# RZT2H register map
Vendor: Renesas Electronics Corporation; Series: RZT; File version: 1.00.00
CPU: other r0p0, little endian, MPU, no FPU, VTOR, 4 interrupt priority bits, 624 interrupts
Registers are 32-bit, read-write, reset 0x0 unless marked. A register's access mark holds for its fields unless they carry their own. Offsets are from the block's base; [hi:lo] are bit positions.

## USBHC — USB 2.0 HS Host Module
Base 0x92040000
0x00 HCREVISION ro reset 0x10
  [7:0] REV — HCI revision
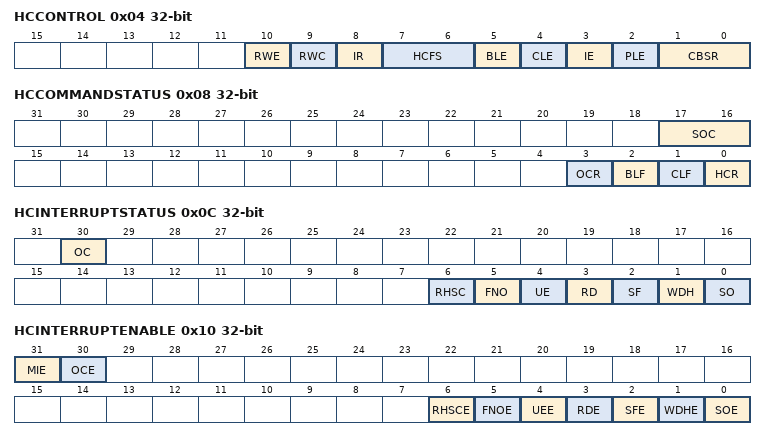
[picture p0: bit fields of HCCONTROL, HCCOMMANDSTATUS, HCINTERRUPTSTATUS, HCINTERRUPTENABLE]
0x04 HCCONTROL
  [10] RWE — PME assertion control (RemoteWakeUpEnable)
  [9] RWC — Remote Wakeup support setting (RemoteWakeUpConnect)
    0=Remote Wakeup is not supported; 1=Remote Wakeup is supported
  [8] IR — HcInterruptStatus interrupt path setting (InterruptRouting)
  [7:6] HCFS — Host logic operation status (Host Controller FunctionalState)
    0=USB Reset; 1=USB Resume; 2=USB Operational; 3=USB Suspend
  [5] BLE — Bulk list processing setting (BulkListEnable)
    0=Bulk list processing is not done; 1=Bulk list processing is done
  [4] CLE — Control list processing setting (ControlListEnable)
    0=Control list processing is not done; 1=Control list processing is done
  [3] IE — Isochronous ED processing setting (IsochronousEnable)
    0=Isochronous ED processing is enabled; 1=Isochronous ED processing is disabled
  [2] PLE — Periodic list setting (PeriodicListEnable)
    0=Periodic list processing is not done; 1=Period list processing is done
  [1:0] CBSR — Control/bulk transfer service ratio (ControlBulkServiceRatio)
0x08 HCCOMMANDSTATUS
  [17:16] SOC ro — Schedule overrun count (Scheduling OverrunCount)
  [3] OCR wo — Host logic control right change (OwnershipChangeRequest)
  [2] BLF — Bulk list TD (BulkListFilled)
    0=TD exists in the bulk list; 1=TD does not exist in the bulk list
  [1] CLF — Control list TD (ControlList Filled)
    0=TD exists in the control list; 1=TD does not exist in the control list
  [0] HCR wo — Host logic software reset start (HostController Reset)
0x0C HCINTERRUPTSTATUS
  [30] OC — Host logic control right change (OwnershipChange)
  [6] RHSC — HcRhStatus/HcRhPortStatus register status (RootHubStatus Change)
    0=No RHSC interrupt has occurred; 1=RHSC interrupt has occurred
  [5] FNO — FrameNumber bit MSB change (Frame Number Overflow)
    0=No FNO interrupt has occurred; 1=FNO interrupt has occurred
  [4] UE — USB non-related system error detection (Unrecoverable Error)
    0=No UE interrupt has occurred; 1=UE interrupt has occurred
  [3] RD — Resume detection (Resume Detected)
    0=No RD interrupt has occurred; 1=RD interrupt has occurred
  [2] SF — HccaFrameNumber update (StartOfFrame)
    0=No SF interrupt has occurred; 1=SF interrupt has occurred
  [1] WDH — Host logic HccaDoneHead update (Writeback Done Head)
    0=No WDH interrupt has occurred; 1=WDH interrupt has occurred
  [0] SO — USB schedule overrun (Scheduling Overrun)
    0=No SO interrupt has occurred; 1=SO interrupt has occurred
0x10 HCINTERRUPTENABLE
  [31] MIE — Interrupt 8 source enable (MasterInterrupt Enable)
    0=No monitoring and nothing is to be done; 1=The specified interrupt is enabled
  [30] OCE — OC interrupt source enable (OwnershipChangeEnable)
    0=No monitoring and nothing is to be done; 1=OC interrupt is enabled
  [6] RHSCE — RHSC interrupt source enable (RootHubStatus ChangeEnable)
    0=No monitoring and nothing is to be done; 1=RHSC interrupt is enabled
  [5] FNOE — FNO interrupt source enable (FrameNumber OverflowEnable)
    0=No monitoring and nothing is to be done; 1=FNO interrupt is enabled
  [4] UEE — UE interrupt source enable (Unrecoverable ErrorEnable)
    0=No monitoring and nothing is to be done; 1=UE interrupt is enabled
  [3] RDE — RD interrupt source enable (Resume DetectedEnable)
    0=No monitoring and nothing is to be done; 1=RD interrupt is enabled
  [2] SFE — SF interrupt source enable (StartOfFrame)
    0=No monitoring and nothing is to be done; 1=SF interrupt is enabled
  [1] WDHE — WDH interrupt source enable (WritebackDone HeadEnable)
    0=No monitoring and nothing is to be done; 1=WDH interrupt is enabled
  [0] SOE — SO interrupt source enable (Scheduling OverrunEnable)
    0=No monitoring and nothing is to be done; 1=SO interrupt is enabled
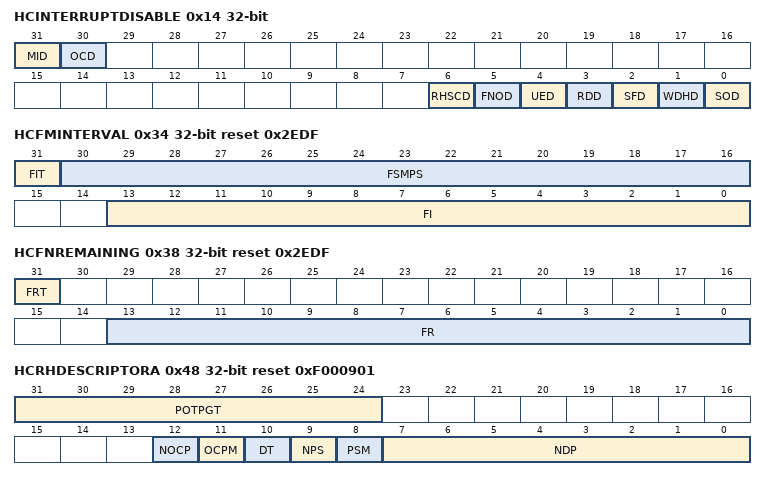
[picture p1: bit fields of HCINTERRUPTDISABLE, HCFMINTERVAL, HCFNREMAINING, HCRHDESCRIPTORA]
0x14 HCINTERRUPTDISABLE
  [31] MID — Interrupt 8 source disable (Master Interrupt Disable)
    0=Nothing is to be done; 1=The interrupt set is disabled
  [30] OCD — OC interrupt source disable (OwnershipChangeDisable)
    0=Nothing is to be done; 1=OC is deleted from the interrupt sources
  [6] RHSCD — RHSC interrupt source disable (RootHub StatusChange Disable)
    0=Nothing is to be done; 1=The interrupt source RHSC is disabled
  [5] FNOD — FNO interrupt source disable (FrameNumberOverflow Disable)
    0=Nothing is to be done; 1=The interrupt source FNO is disabled
  [4] UED — UE interrupt source disable (Unrecoverable ErrorDisable)
    0=Nothing is to be done; 1=The interrupt source UE is disabled
  [3] RDD — RD interrupt source disable (Resume Detected Disable)
    0=Nothing is to be done; 1=The interrupt source RD is disabled
  [2] SFD — SF interrupt source disable (StartOfFrame Disable)
    0=Nothing is to be done; 1=The interrupt source SF is disabled
  [1] WDHD — WDH interrupt source disable (Writeback DoneHead Disable)
    0=Nothing is to be done; 1=The interrupt source WDH is disabled
  [0] SOD — SO interrupt source disable (Scheduling Overrun Disable)
    0=Nothing is to be done; 1=The interrupt source SO is disabled
0x18 HCHCCA
  [31:8] RAMBA — RAM base address setting
0x1C HCPERIODCCURRENTIED ro — HcPeriodicCurrentED Register
  [31:4] PCED — ED physical address (PeriodicCurrentED)
0x20 HCCONTROLHEADED
  [31:4] CHED — Start ED physical address (ControlHeadED)
0x24 HCCONTROLCURRENTED
  [31:4] CCED — ED physical address (ControlCurrentED)
0x28 HCBULKHEADED
  [31:4] BHED — Start ED physical address (BulkHeadED)
0x2C HCBULKCURRENTED
  [31:4] BCED — ED physical address (BulkCurrentED)
0x30 HCDONEHEAD ro
  [31:4] DH — HcDoneHead physical address (DoneHead)
0x34 HCFMINTERVAL reset 0x2EDF
  [31] FIT — Frame synchronization (FrameInterval Toggle)
  [30:16] FSMPS — FS transfer packet maximum size setting (FSLagest DataPacket)
  [13:0] FI — Frame interval setting (FrameInterval)
0x38 HCFNREMAINING ro reset 0x2EDF — HcFmRemaining Register
  [31] FRT — Frame synchronization (FrameRemainingToggle)
  [13:0] FR — Down counter frame (FrameRemaining)
0x3C HCFMNUMBER ro
  [15:0] FN — Elapsed frame number (FrameNumber)
0x40 HCPERIODSTART — HcPeriodicStart Register
  [13:0] PS — Periodic list processing start time (PeriodicStart)
0x44 HCLSTHRESHOLD reset 0x628
  [11:0] LS — Transferrable threshold (LSThreshold)
0x48 HCRHDESCRIPTORA reset 0xF000901
  [31:24] POTPGT — Wait time (PowerOnToPowerGood Time)
  [12] NOCP — Overcurrent function support (NoOver Current Protection)
    0=Overcurrent protection function is supported; 1=Overcurrent protection function is not supported
  [11] OCPM — Overcurrent state reporting (OverCurrentProtection Mode)
    0=Overcurrent state of all ports is collectively reported; 1=Overcurrent state of each port is separately reported
  [10] DT ro — Device type (DeviceType)
  [9] NPS — Power control (NoPower Switching)
    0=Port power can be switched on and off; 1=Port power is always turned on while the host logic is operating
  [8] PSM — Power switch control (PowerSwitchingMode)
    0=Power to all ports is controlled together; 1=Power to each port is separately controlled
  [7:0] NDP ro — Downstream port number (NumberDownstreamPorts)
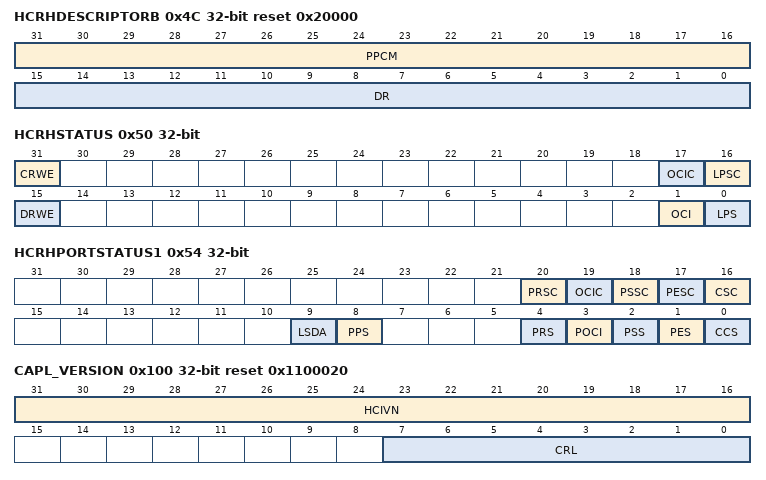
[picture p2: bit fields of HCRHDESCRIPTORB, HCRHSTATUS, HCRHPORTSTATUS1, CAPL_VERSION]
0x4C HCRHDESCRIPTORB reset 0x20000
  [31:16] PPCM — Port Power Control Mask
  [15:0] DR — Device Removable
0x50 HCRHSTATUS
  [31] CRWE wo — DRWE bit clear (Clear Remote Wakeup Enable)
    0=No effect; 1=Clears the DRWE bit
  [17] OCIC — OCI bit change report (OverCurrent Indicate Change)
    0=Nothing is to be done in case of an overcurrent; 1=OverCurrent state has changed
  [16] LPSC — Local power status change (LocalPowerStatusChange)
  [15] DRWE — Device remote start enable (DeviceRemoteWakeupEnable)
    0=ConnectStatusChange is not a RemoteWakeup source; 1=ConnectStatusChange is a RemoteWakeup source
  [1] OCI ro — Overcurrent indicator (OverCurrent Indicator)
    0=Port is in normal state; 1=Port is in overcurrent state
  [0] LPS — Local power status (LocalPowerStatus)
0x54 HCRHPORTSTATUS1
  [20] PRSC — Port reset complete (PortReset StatusChange)
    0=Port reset has not been completed, or nothing is to be done regarding the PRS bit; 1=Port reset has been completed
  [19] OCIC — Overcurrent state detection (OverCurrent IndicateChange)
    0=Nothing is to be done regarding overcurrent state; 1=Overcurrent state has changed
  [18] PSSC — RESUME sequence complete (PortSuspend StatusChange)
    0=RESUME has not been completed; 1=RESUME has been completed
  [17] PESC — PES bit status (PortEnable StatusChange)
    0=Nothing is to be done regarding PES; 1=PES state has changed
  [16] CSC — CCS bit status (ConnectStatus Change)
    0=Nothing is to be done regarding CCS; 1=CCS has changed
  [9] LSDA — Device speed (LowSpeedDeviceAttached)
    0=FS device is connected; 1=LS device is connected
  [8] PPS — Power status (PortPowerStatus)
    0=Port power is off; 1=Port power is on
  [4] PRS — Port reset status (PortResetStatus)
    0=Port reset is not in progress; 1=Port reset is in progress
  [3] POCI ro — Downstream port overcurrent detection (PortOverCurrentIndicator)
    0=Port is in normal state; 1=Port is in overcurrent state
  [2] PSS — Suspend/Resume status (PortSuspendStatus)
    0=Port is in normal transfer state; 1=Port is in suspend state
  [1] PES — Port enable status (PortEnableStatus)
    0=Port is disabled; 1=Port is enabled
  [0] CCS — Connection status indication (CurrentConnectStatus)
    0=No device is connected; 1=Device is connected
0x100 CAPL_VERSION ro reset 0x1100020 — Capability Registers Length and EHCI Version Number Register
  [31:16] HCIVN — EHCI Version Number
  [7:0] CRL — Capability Registers Length
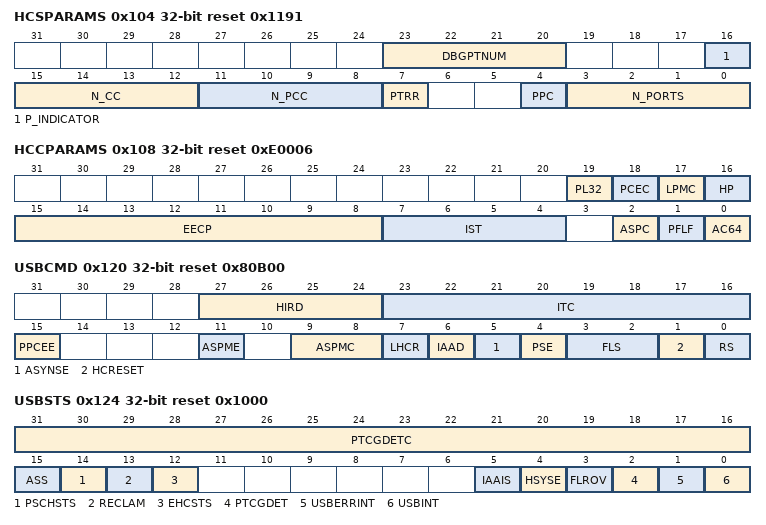
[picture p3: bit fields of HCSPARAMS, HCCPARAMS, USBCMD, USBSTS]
0x104 HCSPARAMS ro reset 0x1191 — Structural Parameters Register
  [23:20] DBGPTNUM — Debug port number
  [16] P_INDICATOR — Port indicator control support
  [15:12] N_CC — Number of OHCI host logic (Number of Companion Controller)
  [11:8] N_PCC — Number of ports (Number of Ports per Companion Controller)
  [7] PTRR — Port routing rules
  [4] PPC — Port power control (Port Power Control)
    0=Port power is always on; 1=Port power is controlled using bit 12 (PP) in the PORTSC1 register
  [3:0] N_PORTS — Number of downstream ports (Number of Ports)
    1=1 port; other=Others (Reserved)
0x108 HCCPARAMS ro reset 0xE0006 — Capability Parameters Register
  [19] PL32 — 32-frame periodic list capability
  [18] PCEC — Per-port change event capability
  [17] LPMC — Link power management capability
  [16] HP — Hardware prefetch capability
  [15:8] EECP — Offset address (EHCI Extend Capabilities Pointer)
  [7:4] IST — Isochronous data structure threshold
  [2] ASPC — Asynchronous schedule park support capability
  [1] PFLF — Programming frame list flag
  [0] AC64 — Memory pointer selection
0x10C HCSP_PORTROUTE ro — Companion Port Route Description Register
0x120 USBCMD reset 0x80B00 — USB Command Register
  [27:24] HIRD — Host-Initiated Resume Duration (Minimum K-state drive time)
  [23:16] ITC — Host logic interrupt generation maximum rate (Interrupt Threshold Control)
    1=1 micro-frame; 2=2 micro-frames; 4=4 micro-frames; 8=8 micro-frames (1 ms); 16=16 micro-frames (2 ms); 32=32 micro-frames (4 ms); 64=64 micro-frames (8 ms)
  [15] PPCEE — Per-port change event enable
  [11] ASPME — Asynchronous schedule park mode enable
    0=Disabled; 1=Enabled
  [9:8] ASPMC — Asynchronous schedule park mode count
  [7] LHCR ro — Light host controller reset execution status
  [6] IAAD — Interrupt on Async Advance Doorbell
  [5] ASYNSE — Asynchronous schedule enable
    0=Asynchronous list processing is not executed (skipped); 1=Asynchronous list processing is executed using the ASYNCLISTADDR register
  [4] PSE — Periodic schedule enable
    0=Periodic list processing is not executed (skipped); 1=Periodic list processing is executed using the PERIODICLISTBASE register
  [3:2] FLS — Frame list size
    0=1024 elements (4096 bytes); 1=512 elements (2048 bytes); 2=256 elements (1024 bytes); 3=32 elements (128 bytes)
  [1] HCRESET — Host logic initialization (Host Controller Reset)
  [0] RS — EHCI host logic run/stop (Run/Stop)
    0=Stopped (the host logic has completed transactions and halted); 1=Activated (the host logic executes the schedule)
0x124 USBSTS reset 0x1000 — USB Status Register
  [31:16] PTCGDETC — Port-n Change Detect
  [15] ASS ro — Asynchronous schedule status
    0=Asynchronous schedule is disabled; 1=Asynchronous schedule is enabled
  [14] PSCHSTS ro — Periodic schedule status
    0=Periodic schedule is disabled; 1=Periodic schedule is enabled
  [13] RECLAM ro — Empty asynchronous schedule detection (Reclamation)
  [12] EHCSTS ro — EHCI host logic status (HCHalted)
    0=EHCI host logic is in execution; 1=EHCI host logic is stopped
  [5] IAAIS — Async advance interrupt status
    0=No Async Advance interrupt has occurred; 1=Async Advance interrupt state has been detected
  [4] HSYSE — Host system error
    0=No system error has occurred; 1=System error has occurred
  [3] FLROV — Frame list rollover
    0=Frame list has not returned to 0x000; 1=Frame list has returned to 0x000
  [2] PTCGDET — Port state change detection
  [1] USBERRINT — USB transaction status (USB Error Interrupt)
    0=USB transaction has been completed normally; 1=USB transaction has ended with an error
  [0] USBINT — USB transfer complete (USB Interrupt)
    0=USB transfer has not been completed; 1=USB transfer has been completed
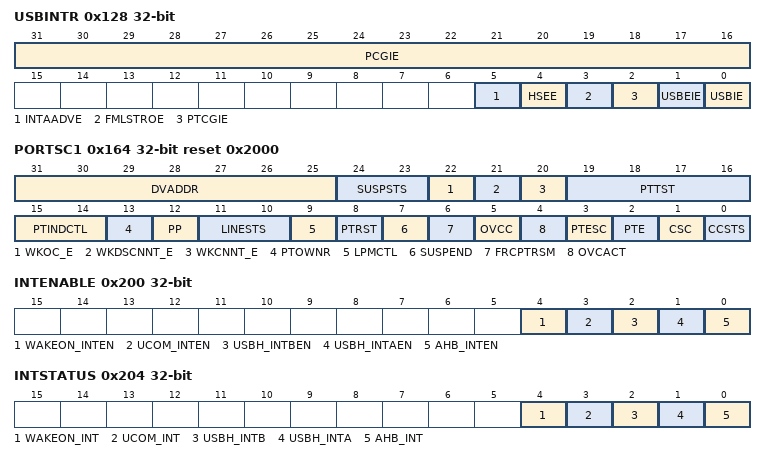
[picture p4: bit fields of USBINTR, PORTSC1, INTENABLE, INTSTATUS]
0x128 USBINTR — USB Interrupt Enable Register
  [31:16] PCGIE — Port-n Change Interrupt Enable
  [5] INTAADVE — Interrupt on async advance enable
    0=Disabled; 1=Enabled (interrupt indicated by the Interrupt on Async Advance bit)
  [4] HSEE — Host system error enable
    0=Disabled; 1=Enabled (interrupt indicated by the Host System Error bit)
  [3] FMLSTROE — Frame list rollover enable
    0=Disabled; 1=Enabled (interrupt indicated by the Frame List Rollover bit)
  [2] PTCGIE — Port change interrupt enable
    0=Disabled; 1=Enabled (interrupt indicated by the Port Change Detect bit)
  [1] USBEIE — USB error interrupt enable
    0=Disabled; 1=Enabled (interrupt indicated by the USBERRINT bit)
  [0] USBIE — USB interrupt enable
    0=Disabled; 1=Enabled (interrupt indicated by the USBINT bit)
0x12C FRINDEX — USB Frame Index Register
  [13:0] FRAMEINDEX
0x130 CTRLDSSEGMENT ro — Control Data Structure Segment Register
0x134 PERIODICLISTBASE — Periodic Frame List Base Address Register
  [31:12] PFLSA — Periodic frame list start address
0x138 ASYNCLISTADDR — Next Asynchronous List Address Register
  [31:5] LPL — Asynchronous Queue Head link pointer address (Link Pointer Low)
0x160 CONFIGFLAG — Configure Flag Register
  [0] CF — Port routing control circuit configuration flag (Configure Flag)
    0=Port routing control circuit routes each port to the OHCI host logic by default; 1=Port routing control circuit routes each port to the EHCI host logic by default
0x164 PORTSC1 reset 0x2000 — Port 1 Status and Control Register
  [31:25] DVADDR — USB device address
  [24:23] SUSPSTS — Suspend status
    0=Device successfully entered the L1 state (ACK is received from the device); 1=Device was unable to enter the L1 state at this time (NYET is received from the device); 2=Device does not support L1 state transitions (STALL is received from the device); 3=Other than above (such as a timeout error)
  [22] WKOC_E — Overcurrent state detection enable (Wake on Over-current Enable)
  [21] WKDSCNNT_E — Device disconnection detection enable (Wake on Disconnect Enable)
  [20] WKCNNT_E — Device connection detection enable (Wake on Connect Enable)
  [19:16] PTTST — Pin test control
  [15:14] PTINDCTL ro — As the host logic does not support the port indicator control function, these bits are set to 00b.
  [13] PTOWNR — Port ownership
    0=EHCI has the port ownership; 1=OHCI has the port ownership
  [12] PP — Port Power Supply Control (Port Power)
    0=No power is supplied to the port; 1=Power is supplied to the port
  [11:10] LINESTS ro — D+/D- logic level
  [9] LPMCTL — LPM control
    0=Suspend using L2; 1=Suspend using L1 (LPM)
  [8] PTRST — Port reset status
    0=Port is not in reset state; 1=Port is in reset state
  [7] SUSPEND — Port suspend
    0=Port is not in suspend state; 1=Port is in suspend state
  [6] FRCPTRSM — Force Port Resume (Port resume detection flag)
    0=Resume (K-state) has not been detected or output; 1=Resume (K-state) has been detected or output
  [5] OVCC — Over-current Change
    0=Value of bit 4 (OVCACT) has not changed; 1=Value of bit 4 (OVCACT) has changed
  [4] OVCACT ro — Port overcurrent status
    0=Port is not in overcurrent state; 1=Port is in overcurrent state
  [3] PTESC — Port enable/disable status change
    0=Frame babble error has not occurred; 1=Frame babble error has been detected
  [2] PTE — Port enable/disable status
    0=Port is disabled; 1=Port is enabled
  [1] CSC — Connect status change
    0=Value of bit 0 (Current Connect Status) has not changed; 1=Value of bit 0 (Current Connect Status) has changed
  [0] CCSTS ro — Port connection status
    0=No device is connected to the port; 1=Device is connected to the port
0x200 INTENABLE
  [all] fields
    0=Disabled; 1=Enabled
  [4] WAKEON_INTEN — WAKEON_INT bit control
  [3] UCOM_INTEN — UCOM_INT bit control
  [2] USBH_INTBEN — USBH_INTB bit control
  [1] USBH_INTAEN — USBH_INTA bit control
  [0] AHB_INTEN — AHB_INT bit control
0x204 INTSTATUS
  [4] WAKEON_INT — WAKEON interrupt status
    0=WAKEON interrupt has not occurred; 1=WAKEON interrupt has occurred
  [3] UCOM_INT ro — UCOM register interrupt status
    0=UCOM register interrupt has not occurred; 1=UCOM register interrupt has occurred
  [2] USBH_INTB ro — USBH_INTB EHCI interrupt status
    0=INTB interrupt has not occurred; 1=INTB interrupt has occurred
  [1] USBH_INTA ro — OHCI interrupt status
    0=INTA interrupt has not occurred; 1=INTA interrupt has occurred
  [0] AHB_INT — AHB bus error indication
    0=AHB bus error has not occurred; 1=AHB bus error has occurred
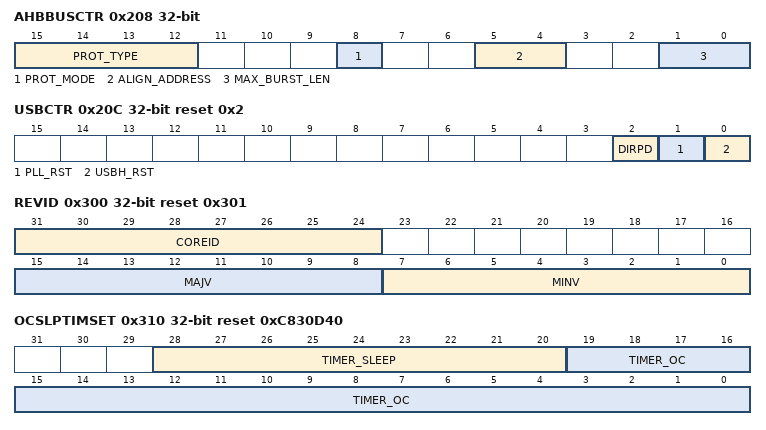
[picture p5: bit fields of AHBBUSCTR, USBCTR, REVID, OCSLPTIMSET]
0x208 AHBBUSCTR
  [15:12] PROT_TYPE — These bits set MHPROT[3:0] when the AHB master interface initiates a transfer.
  [8] PROT_MODE — This bit selects the MHPROT[3:0] mode when the AHB master interface initiates a transfer.
    0=Value of PROT_TYPE[3:0] is output as MHPROT[3:0]; 1=0000b is set as MHPROT[3:0] for DMA transfer when the last data of a burst is transferred. The value of PROT_TYPE[3:0] is used as MHPROT[3:0] for other data in a burst.
  [5:4] ALIGN_ADDRESS — Address boundary setting
    0=1-KB boundary is not exceeded when initiating a burst transfer; 1=64-byte boundary is not exceeded when initiating a burst transfer; 2=32-byte boundary is not exceeded when initiating a burst transfer (The maximum burst length is INCR8 in this case. The 32-byte boundary is exceeded when the maximum burst length is INCR16.); 3=16-byte boundary is not exceeded when initiating a burst transfer. (The maximum burst length is INCR4 in this case. The 16-byte boundary is exceeded when the maximum burst length is INCR8 or greater.)
  [1:0] MAX_BURST_LEN — Maximum burst length
    0=INCR16; 1=INCR8; 2=INCR4; 3=SINGLE
0x20C USBCTR reset 0x2
  [2] DIRPD — Direct transition to power-down state
    0=Normal operation; 1=Direct power-down state
  [1] PLL_RST — Reset of USB PHY PLL
    0=Release PLL reset; 1=Assert PLL reset
  [0] USBH_RST wo — Software reset for the core
    0=Nothing occurs; 1=Host logic is reset
0x300 REVID ro reset 0x301 — Revision and Core ID Register
  [31:24] COREID
  [15:8] MAJV — Major Version
  [7:0] MINV — Minor Version
0x310 OCSLPTIMSET reset 0xC830D40 — Overcurrent Detection/Sleep Timer Setting Register
  [28:20] TIMER_SLEEP — Detection/Sleep Timer Setting
  [19:0] TIMER_OC — Overcurrent Timer setting
0x800 COMMCTRL reset 0x80000000 — Common Control Register
  [31] PERI — USB mode setting
    0=Host mode; 1=Function mode
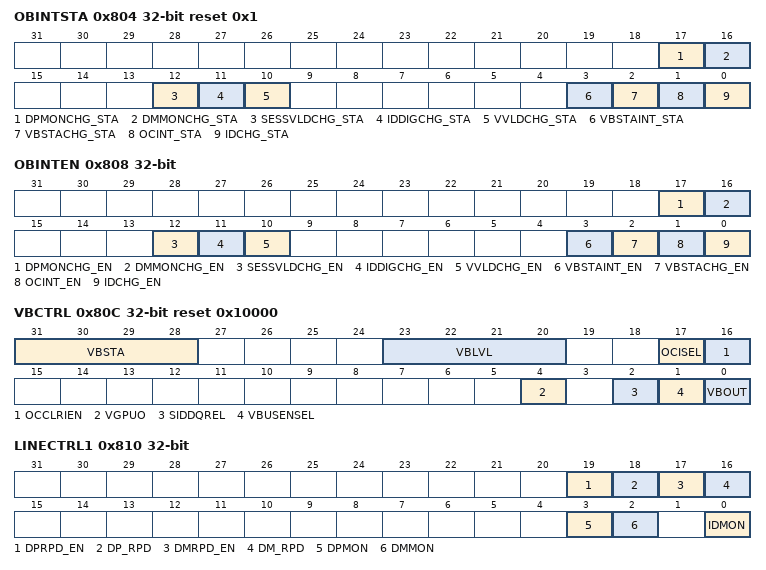
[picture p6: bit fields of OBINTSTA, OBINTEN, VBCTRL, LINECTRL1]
0x804 OBINTSTA reset 0x1 — OTG-BC Interrupt Status Register
  [17] DPMONCHG_STA — DPMON change status
    0=The DPMON bit of the LINECTRL1 register has not changed; 1=The DPMON bit of the LINECTRL1 register has changed
  [16] DMMONCHG_STA — DMMON change status
    0=The DMMON bit of the LINECTRL1 register has not changed; 1=The DMMON bit of the LINECTRL1 register has changed
  [12] SESSVLDCHG_STA — OTGSESSVLD change status
    0=The OTGSESSVLD bit of the PHYCTRL register has not changed; 1=The OTGSESSVLD bit of the PHYCTRL register has changed
  [11] IDDIGCHG_STA — IDDIG0 change status
    0=The IDDIG0 bit of the PHYCTRL register has not changed; 1=The IDDIG0 bit of the PHYCTRL register has changed
  [10] VVLDCHG_STA — VBUSVALID change status
    0=The VBUSVALID bit of the PHYCTRL register has not changed; 1=The VBUSVALID bit of the PHYCTRL register has changed
  [3] VBSTAINT_STA — VBUS voltage status interrupt
    0=Value of VBSTA[3:0] bits is not the same as the value of the VBLVL[3:0] bits; 1=Value of VBSTA[3:0] bits is the same as the value of the VBLVL[3:0] bits
  [2] VBSTACHG_STA — VBSTA[3:0] change status
    0=Value of the VBSTA[3:0] bits has not changed; 1=Value of the VBSTA[3:0] bits has changed
  [1] OCINT_STA — USB_OVRCUR assertion status
    0=USB_OVRCUR pin is not asserted (remains 1); 1=USB_OVRCUR pin is asserted (change to 0)
  [0] IDCHG_STA — USB_OTG_ID change status
    0=Value input from the USB_OTG_ID pin has not changed; 1=Value input from the USB_OTG_ID pin has changed
0x808 OBINTEN — OTG-BC Interrupt Enable Register
  [17] DPMONCHG_EN — DPMONCHG_STA interrupt enable
    0=Interrupt flagged by the DPMONCHG_STA bit disabled; 1=Interrupt flagged by the DPMONCHG_STA bit enabled
  [16] DMMONCHG_EN — DMMONCHG_STA interrupt enable
    0=Interrupt flagged by the DMMONCHG_STA bit disabled; 1=Interrupt flagged by the DMMONCHG_STA bit enabled
  [12] SESSVLDCHG_EN — SESSVLDCHG_STA interrupt enable
    0=Interrupt flagged by the SESSVLDCHG_STA bit disabled; 1=Interrupt flagged by the SESSVLDCHG_STA bit enabled
  [11] IDDIGCHG_EN — IDDIGCHG_STA interrupt enable
    0=Interrupt flagged by the IDDIGCHG_STA bit disabled; 1=Interrupt flagged by the IDDIGCHG_STA bit enabled
  [10] VVLDCHG_EN — VVLDCHG_STA interrupt enable
    0=Interrupt flagged by the VVLDCHG_STA bit disabled; 1=Interrupt flagged by the VVLDCHG_STA bit enabled
  [3] VBSTAINT_EN — VBSTAINT_STA interrupt enable
    0=Interrupt flagged by the VBSTAINT_STA bit is disabled; 1=Interrupt flagged by the VBSTAINT_STA bit is enabled
  [2] VBSTACHG_EN — VBSTACHG_STA interrupt enable
    0=Interrupt flagged by the VBSTACHG_STA bit is disabled; 1=Interrupt flagged by the VBSTACHG_STA bit is enabled
  [1] OCINT_EN — OCINT_STA interrupt enable
    0=Interrupt flagged by the OCINT_STA bit is disabled; 1=Interrupt flagged by the OCINT_STA bit is enabled
  [0] IDCHG_EN — IDCHG_STA Interrupt enable
    0=Interrupt flagged by the IDCHG_STA bit is disabled; 1=Interrupt flagged by the IDCHG_STA bit is enabled
0x80C VBCTRL reset 0x10000 — VBUS Control Register
  [31:28] VBSTA ro — VBUS indication
  [23:20] VBLVL — VBUS level detection
  [17] OCISEL — Overcurrent detection
    0=OCI signal that is output by the host logic This signal is treated as an indication of an overcurrent if the USB_OVRCUR pin is asserted longer than the overcurrent detection time set in bits [19:0] (TIMER_OC[19:0]) in the OCSLPTIMSET register; 1=Inverted signal from the USB_OVRCUR pin When this signal is selected, the overcurrent detection time set in the TIMER_OC[19:0] bits is not used. The system assumes an overcurrent has occurred if the USB_OVRCUR pin is asserted for 5 clock cycles or more.
  [16] OCCLRIEN — USB_VBUSEN pin control at occurrence of overcurrent
    0=VBOUT bit is not automatically cleared if an overcurrent occurs; 1=VBOUT bit is automatically cleared if an overcurrent occurs
  [4] VGPUO — USB_EXICEN pin control
    0=USB_EXICEN is driven to low; 1=USB_EXICEN is driven to high
  [2] SIDDQREL — SIDDQ mode control
    0=SIDDQ mode is set; 1=SIDDQ mode is released
  [1] VBUSENSEL — USB_VBUSEN pin control
    0=USB_VBUSEN is controlled by PPON1; 1=USB_VBUSEN is controlled by VBOUT bit in this register
  [0] VBOUT — VBUS drive control (USB_VBUSEN pin)
    0=VBUS output is disabled. (USB_VBUSEN is driven to low.); 1=VBUS output is enabled. (USB_VBUSEN is driven to high.)
0x810 LINECTRL1 (reset mask 0xFFFFFFFE) — Line Control Port 1 Register
  [19] DPRPD_EN — Enables DP_RPD to control USB bus (DP) 15 kOhm pulldown resistor.
    0=Control of DP-side 15 kOhm pulldown resistor by DP_RPD disabled; 1=Control of DP-side 15 kOhm pulldown resistor by DP_RPD enabled
  [18] DP_RPD — Controls USB bus (DP) 15 kOhm pulldown resistor when DRPPD_EN = 1.
    0=DP-side 15 kOhm pulldown resistor is OFF; 1=DP-side 15 kOhm pulldown resistor is ON
  [17] DMRPD_EN — Enables DM_RPD to control USB bus (DM) 15 kOhm pulldown resistor.
    0=Control of DM-side 15 kOhm pulldown resistor by DM_RPD disabled; 1=Control of DM-side 15 kOhm pulldown resistor by DM_RPD enabled
  [16] DM_RPD — Controls USB bus (DM) 15 kOhm pulldown resistor when DMPPD_EN = 1.
    0=DM-side 15 kOhm pulldown resistor is OFF; 1=DM-side 15 kOhm pulldown resistor is ON
  [3] DPMON ro — Indicates a value of USB bus DP.
  [2] DMMON ro — Indicates a value of USB bus DM.
  [0] IDMON ro — Indicates a value of USB_OTG_ID input pin.
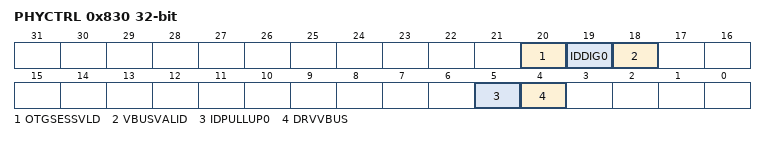
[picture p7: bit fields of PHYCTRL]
0x830 PHYCTRL — PHY Control Register
  [20] OTGSESSVLD ro — OTG Device Session Valid Indicator
    0=OTG Device Session is no valid; 1=OTG Device Session is valid
  [19] IDDIG0 ro — Mini A/B Plug Indicator
    0=The connected plug is a mini-A plug; 1=The connected plug is a mini-B plug
  [18] VBUSVALID ro — VBUS Valid Indicator
    0=USB_VUBUSIN level is not valid; 1=USB_VUBUSIN level is valid
  [5] IDPULLUP0 — ID Input Sample Enable
    0=ID pin sampling is disabled, and the IDDIG0 bit is not valid; 1=ID pin sampling is enabled, and the IDDIG0 bit is valid
  [4] DRVVBUS — Drive VBUS
    0=The VBUS Valid comparator is disabled; 1=The VBUS Valid comparator is enabled
